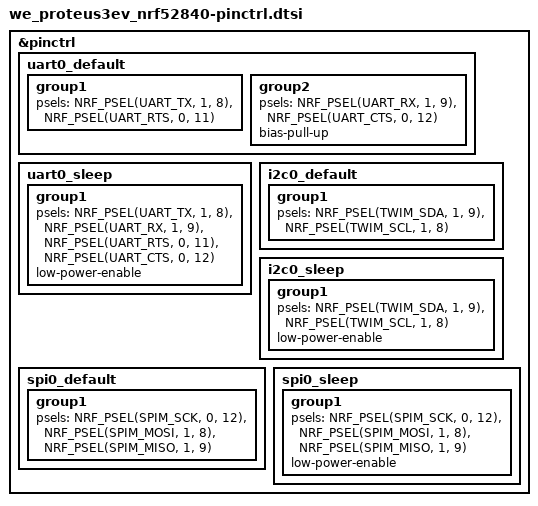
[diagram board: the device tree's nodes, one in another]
&pinctrl {
	uart0_default: uart0_default {
		group1 {
			psels = <NRF_PSEL(UART_TX, 1, 8)>,
				<NRF_PSEL(UART_RTS, 0, 11)>;
		};

		group2 {
			psels = <NRF_PSEL(UART_RX, 1, 9)>,
				<NRF_PSEL(UART_CTS, 0, 12)>;
			bias-pull-up;
		};
	};

	uart0_sleep: uart0_sleep {
		group1 {
			psels = <NRF_PSEL(UART_TX, 1, 8)>,
				<NRF_PSEL(UART_RX, 1, 9)>,
				<NRF_PSEL(UART_RTS, 0, 11)>,
				<NRF_PSEL(UART_CTS, 0, 12)>;
			low-power-enable;
		};
	};

	i2c0_default: i2c0_default {
		group1 {
			psels = <NRF_PSEL(TWIM_SDA, 1, 9)>,
				<NRF_PSEL(TWIM_SCL, 1, 8)>;
		};
	};

	i2c0_sleep: i2c0_sleep {
		group1 {
			psels = <NRF_PSEL(TWIM_SDA, 1, 9)>,
				<NRF_PSEL(TWIM_SCL, 1, 8)>;
			low-power-enable;
		};
	};

	spi0_default: spi0_default {
		group1 {
			psels = <NRF_PSEL(SPIM_SCK, 0, 12)>,
				<NRF_PSEL(SPIM_MOSI, 1, 8)>,
				<NRF_PSEL(SPIM_MISO, 1, 9)>;
		};
	};

	spi0_sleep: spi0_sleep {
		group1 {
			psels = <NRF_PSEL(SPIM_SCK, 0, 12)>,
				<NRF_PSEL(SPIM_MOSI, 1, 8)>,
				<NRF_PSEL(SPIM_MISO, 1, 9)>;
			low-power-enable;
		};
	};
};
